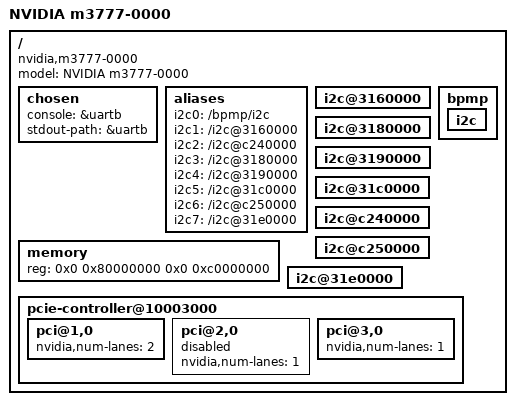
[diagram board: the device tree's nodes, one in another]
/dts-v1/;

#include "tegra186.dtsi"

/ {
	model = "NVIDIA m3777-0000";
	compatible = "nvidia,m3777-0000", "nvidia,tegra186";

	chosen {
		console = &uartb;
		stdout-path = &uartb;
	};

	aliases {
		i2c0 = "/bpmp/i2c";
		i2c1 = "/i2c@3160000";
		i2c2 = "/i2c@c240000";
		i2c3 = "/i2c@3180000";
		i2c4 = "/i2c@3190000";
		i2c5 = "/i2c@31c0000";
		i2c6 = "/i2c@c250000";
		i2c7 = "/i2c@31e0000";
	};

	memory {
		reg = <0x0 0x80000000 0x0 0xc0000000>;
	};

	i2c@3160000 {
		status = "okay";
	};

	i2c@3180000 {
		status = "okay";
	};

	i2c@3190000 {
		status = "okay";
	};

	i2c@31c0000 {
		status = "okay";
	};

	i2c@c240000 {
		status = "okay";
	};

	i2c@c250000 {
		status = "okay";
	};

	i2c@31e0000 {
		status = "okay";
	};

	bpmp {
		i2c {
			status = "okay";
		};
	};

	pcie-controller@10003000 {
		status = "okay";

		pci@1,0 {
			status = "okay";
			nvidia,num-lanes = <2>;
		};

		pci@2,0 {
			status = "disabled";
			nvidia,num-lanes = <1>;
		};

		pci@3,0 {
			status = "okay";
			nvidia,num-lanes = <1>;
		};
	};
};
